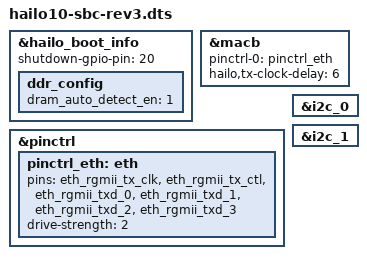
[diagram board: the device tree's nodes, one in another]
// SPDX-License-Identifier: GPL-2.0
/*
 * dts file for Hailo15 SoC
 *
 * Copyright (c) 2019-2025 Hailo Technologies Ltd. All rights reserved.
 */

#include "hailo15-base.dtsi"
#include "hailo15_ddr_configuration.dtsi"
#include "hailo15_ddr_MT53E2G32D4DE-046_regconfig_8GB.dtsi"

&hailo_boot_info {
    shutdown-gpio-pin = <20>;
    ddr_config {
		dram_auto_detect_en = <1>;
    };
};

&macb {
    status = "okay";
    pinctrl-names = "default";
    pinctrl-0 = <&pinctrl_eth>;
    hailo,tx-clock-delay = <6>;
};

&pinctrl {
    pinctrl_eth: eth {
        pins = "eth_rgmii_tx_clk",
               "eth_rgmii_tx_ctl",
               "eth_rgmii_txd_0",
               "eth_rgmii_txd_1",
               "eth_rgmii_txd_2",
               "eth_rgmii_txd_3";
        drive-strength = <2>;
    };
};

&i2c_0 {
    status = "okay";
};

&i2c_1 {
    status = "okay";
};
